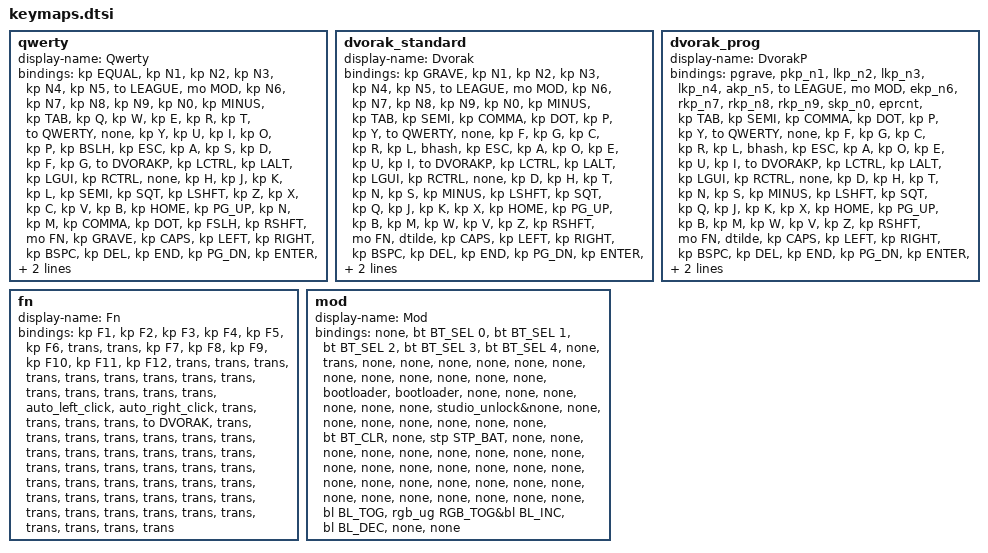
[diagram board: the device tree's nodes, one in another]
qwerty {
    display-name = "Qwerty";
    bindings = <
        &kp EQUAL     &kp N1        &kp N2        &kp N3        &kp N4        &kp N5        &to LEAGUE                                                                                                         &mo MOD       &kp N6        &kp N7        &kp N8        &kp N9        &kp N0        &kp MINUS
        &kp TAB       &kp Q         &kp W         &kp E         &kp R         &kp T         &to QWERTY                                                                                                    &none    &kp Y         &kp U         &kp I         &kp O         &kp P         &kp BSLH
        &kp ESC       &kp A         &kp S         &kp D         &kp F         &kp G         &to DVORAKP                     &kp LCTRL     &kp LALT          &kp LGUI      &kp RCTRL                       &none    &kp H         &kp J         &kp K         &kp L         &kp SEMI      &kp SQT
        &kp LSHFT     &kp Z         &kp X         &kp C         &kp V         &kp B                                                       &kp HOME          &kp PG_UP                                     &kp N         &kp M         &kp COMMA     &kp DOT       &kp FSLH      &kp RSHFT
        &mo FN        &kp GRAVE     &kp CAPS      &kp LEFT      &kp RIGHT                                     &kp BSPC      &kp DEL       &kp END           &kp PG_DN     &kp ENTER     &kp SPACE         &kp UP        &kp DOWN      &kp LBKT      &kp RBKT      &mo FN
    >;
};
dvorak_standard {
    display-name = "Dvorak";
    bindings = <
        &kp GRAVE     &kp N1        &kp N2        &kp N3        &kp N4        &kp N5        &to LEAGUE                                                                                                         &mo MOD       &kp N6        &kp N7        &kp N8        &kp N9        &kp N0        &kp MINUS
        &kp TAB       &kp SEMI      &kp COMMA     &kp DOT       &kp P         &kp Y         &to QWERTY                                                                                                    &none    &kp F         &kp G         &kp C         &kp R         &kp L         &bhash
        &kp ESC       &kp A         &kp O         &kp E         &kp U         &kp I         &to DVORAKP                     &kp LCTRL     &kp LALT          &kp LGUI      &kp RCTRL                       &none    &kp D         &kp H         &kp T         &kp N         &kp S         &kp MINUS
        &kp LSHFT     &kp SQT       &kp Q         &kp J         &kp K         &kp X                                                       &kp HOME          &kp PG_UP                                     &kp B         &kp M         &kp W         &kp V         &kp Z         &kp RSHFT
        &mo FN        &dtilde       &kp CAPS      &kp LEFT      &kp RIGHT                                     &kp BSPC      &kp DEL       &kp END           &kp PG_DN     &kp ENTER     &kp SPACE         &kp UP        &kp DOWN      &kp FSLH      &acaret       &mo FN
    >;
};
dvorak_prog {
    display-name = "DvorakP";
    bindings = <
        &pgrave       &pkp_n1       &lkp_n2       &lkp_n3       &lkp_n4       &akp_n5       &to LEAGUE                                                                                                         &mo MOD       &ekp_n6       &rkp_n7       &rkp_n8       &rkp_n9       &skp_n0       &eprcnt
        &kp TAB       &kp SEMI      &kp COMMA     &kp DOT       &kp P         &kp Y         &to QWERTY                                                                                                    &none    &kp F         &kp G         &kp C         &kp R         &kp L         &bhash
        &kp ESC       &kp A         &kp O         &kp E         &kp U         &kp I         &to DVORAKP                     &kp LCTRL     &kp LALT          &kp LGUI      &kp RCTRL                       &none    &kp D         &kp H         &kp T         &kp N         &kp S         &kp MINUS
        &kp LSHFT     &kp SQT       &kp Q         &kp J         &kp K         &kp X                                                       &kp HOME          &kp PG_UP                                     &kp B         &kp M         &kp W         &kp V         &kp Z         &kp RSHFT
        &mo FN        &dtilde       &kp CAPS      &kp LEFT      &kp RIGHT                                     &kp BSPC      &kp DEL       &kp END           &kp PG_DN     &kp ENTER     &kp SPACE         &kp UP        &kp DOWN      &kp FSLH      &acaret       &mo FN
    >;
};
fn {
    display-name = "Fn";
    bindings = <
        &kp F1        &kp F2        &kp F3        &kp F4        &kp F5        &kp F6        &trans                                                                                                        &trans        &kp F7        &kp F8        &kp F9        &kp F10       &kp F11       &kp F12
        &trans        &trans        &trans        &trans        &trans        &trans        &trans                                                                                                        &trans        &trans        &trans        &trans        &trans        &trans        &trans
        &auto_left_click &auto_right_click &trans        &trans        &trans        &trans        &to DVORAK                          &trans        &trans            &trans        &trans                          &trans        &trans        &trans        &trans        &trans        &trans        &trans
        &trans        &trans        &trans        &trans        &trans        &trans                                                      &trans            &trans                                        &trans        &trans        &trans        &trans        &trans        &trans
        &trans        &trans        &trans        &trans        &trans                                        &trans        &trans        &trans            &trans        &trans        &trans            &trans        &trans        &trans        &trans        &trans
    >;
};
mod {
    display-name = "Mod";
    bindings = <
        &none         &bt BT_SEL 0  &bt BT_SEL 1  &bt BT_SEL 2  &bt BT_SEL 3  &bt BT_SEL 4  &none                                                                                                         &trans        &none         &none         &none         &none         &none         &none
        &none         &none         &none         &none         &none         &none         &bootloader                                                                                                   &bootloader   &none         &none         &none         &none         &none         &none
        &studio_unlock&none         &none         &none         &none         &none         &none                           &none         &none             &bt BT_CLR    &none                           &stp STP_BAT  &none         &none         &none         &none         &none         &none
        &none         &none         &none         &none         &none         &none                                                       &none             &none                                         &none         &none         &none         &none         &none         &none
        &none         &none         &none         &none         &none                                         &none         &none         &none             &none         &none         &bl BL_TOG        &rgb_ug RGB_TOG&bl BL_INC    &bl BL_DEC    &none         &none
    >;
};
#include "league.dtsi"
